# N32H488 register map
Vendor: Nationstech Ltd.; File version: 1.0
Registers are 32-bit, read-write, reset 0x0 unless marked. A register's access mark holds for its fields unless they carry their own. Offsets are from the block's base; [hi:lo] are bit positions; {n}, {i} and the like mark numbered series.

## FMAC — Filter math accelerator
Base 0x40021C00
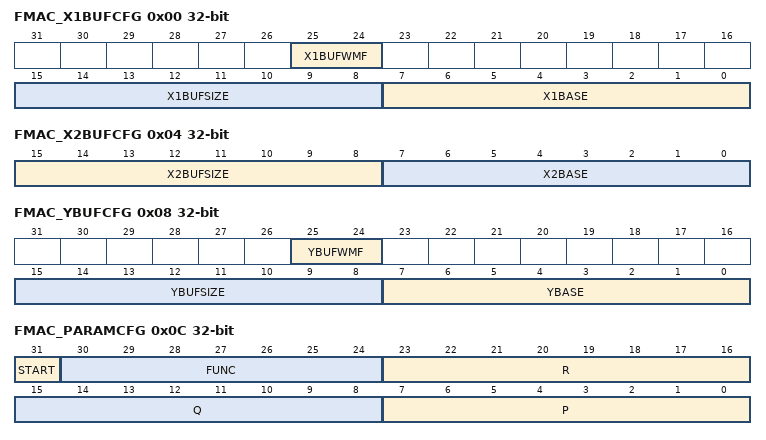
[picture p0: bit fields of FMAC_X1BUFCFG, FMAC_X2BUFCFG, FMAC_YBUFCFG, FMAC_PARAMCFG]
0x00 FMAC_X1BUFCFG
  [25:24] X1BUFWMF, [15:8] X1BUFSIZE, [7:0] X1BASE
0x04 FMAC_X2BUFCFG
  [15:8] X2BUFSIZE, [7:0] X2BASE
0x08 FMAC_YBUFCFG
  [25:24] YBUFWMF, [15:8] YBUFSIZE, [7:0] YBASE
0x0C FMAC_PARAMCFG
  [31] START, [30:24] FUNC, [23:16] R, [15:8] Q, [7:0] P
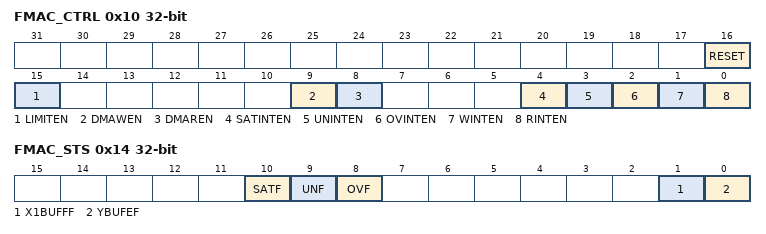
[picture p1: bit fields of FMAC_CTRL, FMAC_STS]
0x10 FMAC_CTRL
  [16] RESET, [15] LIMITEN, [9] DMAWEN, [8] DMAREN, [4] SATINTEN, [3] UNINTEN, [2] OVINTEN, [1] WINTEN, [0] RINTEN
0x14 FMAC_STS
  [10] SATF, [9] UNF, [8] OVF, [1] X1BUFFF, [0] YBUFEF
0x18 FMAC_WDAT
  [15:0] WDAT
0x1C FMAC_RDAT
  [15:0] RDAT

## CORDIC
Base 0x40022400
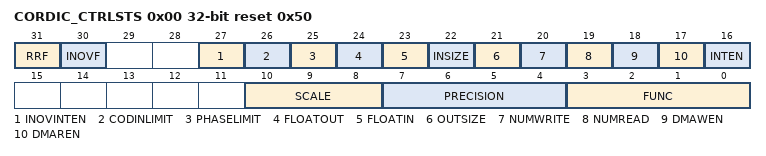
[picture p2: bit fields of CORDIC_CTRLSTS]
0x00 CORDIC_CTRLSTS reset 0x50
  [31] RRF, [30] INOVF, [27] INOVINTEN, [26] CODINLIMIT, [25] PHASELIMIT, [24] FLOATOUT, [23] FLOATIN, [22] INSIZE, [21] OUTSIZE, [20] NUMWRITE, [19] NUMREAD, [18] DMAWEN, [17] DMAREN, [16] INTEN, [10:8] SCALE, [7:4] PRECISION, [3:0] FUNC
0x04 CORDIC_WDAT
0x08 CORDIC_RDAT

## CRC — cyclic redundancy check
Base 0x40021800
0x00 CRC_CRC32CTRL
  [0] RESET
0x04 CRC_CRC32DAT reset 0xFFFFFFFF
0x08 CRC_CRC32IDAT
  [7:0] CRC32IDAT
0x0C CRC_CRC32D reset 0xFFFFFFFF
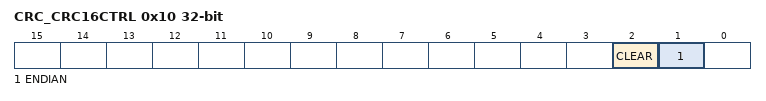
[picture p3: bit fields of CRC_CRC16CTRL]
0x10 CRC_CRC16CTRL
  [2] CLEAR, [1] ENDIAN
0x14 CRC_CRC16DAT
  [7:0] CRC16DAT
0x18 CRC_CRC16D
  [15:0] CRC16D
0x1C CRC_LRC
  [7:0] LRCDAT

## xSPI — Multi-line SPI
Base 0xA0001000
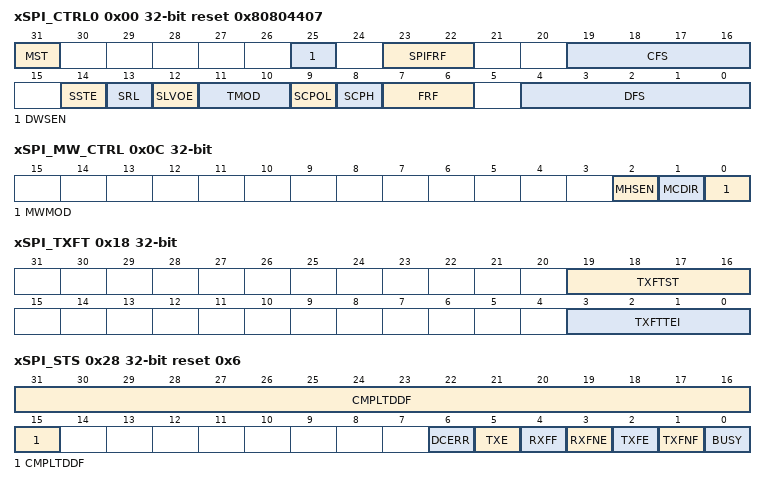
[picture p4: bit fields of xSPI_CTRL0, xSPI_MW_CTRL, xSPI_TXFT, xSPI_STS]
0x00 xSPI_CTRL0 reset 0x80804407
  [31] MST, [25] DWSEN, [23:22] SPIFRF, [19:16] CFS, [14] SSTE, [13] SRL, [12] SLVOE, [11:10] TMOD, [9] SCPOL, [8] SCPH, [7:6] FRF, [4:0] DFS
0x04 xSPI_CTRL1
  [15:0] NDF
0x08 xSPI_EN
  [0] xSPIEN
0x0C xSPI_MW_CTRL
  [2] MHSEN, [1] MCDIR, [0] MWMOD
0x10 xSPI_SLAVE_EN
  [1:0] SEN
0x14 xSPI_BAUD
  [15:1] CLKDIV
0x18 xSPI_TXFT
  [19:16] TXFTST, [3:0] TXFTTEI
0x1C xSPI_RXFT
  [3:0] RXFTTFI
0x20 xSPI_TXFN
  [4:0] TXFN
0x24 xSPI_RXFN
  [4:0] RXFN
0x28 xSPI_STS reset 0x6
  [31:15] CMPLTDDF, [6] DCERR, [5] TXE, [4] RXFF, [3] RXFNE, [2] TXFE, [1] TXFNF, [0] BUSY
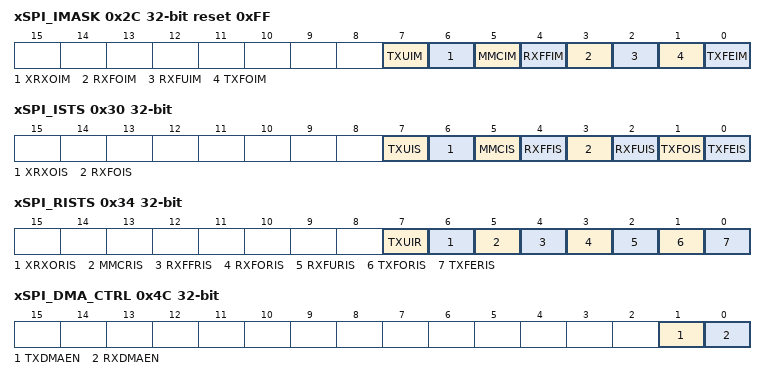
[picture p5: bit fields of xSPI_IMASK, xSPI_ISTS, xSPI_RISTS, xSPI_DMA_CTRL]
0x2C xSPI_IMASK reset 0xFF
  [7] TXUIM, [6] XRXOIM, [5] MMCIM, [4] RXFFIM, [3] RXFOIM, [2] RXFUIM, [1] TXFOIM, [0] TXFEIM
0x30 xSPI_ISTS
  [7] TXUIS, [6] XRXOIS, [5] MMCIS, [4] RXFFIS, [3] RXFOIS, [2] RXFUIS, [1] TXFOIS, [0] TXFEIS
0x34 xSPI_RISTS
  [7] TXUIR, [6] XRXORIS, [5] MMCRIS, [4] RXFFRIS, [3] RXFORIS, [2] RXFURIS, [1] TXFORIS, [0] TXFERIS
0x38 xSPI_TXEICR_CLR
  [0] TXEICR
0x3C xSPI_RXFOI_CLR
  [0] RXFOIC
0x40 xSPI_RXFUI_CLR
  [0] RXFUIC
0x44 xSPI_MMC_CLR
  [0] MMCIC
0x48 xSPI_ICLR
  [0] INTC
0x4C xSPI_DMA_CTRL
  [1] TXDMAEN, [0] RXDMAEN
0x50 xSPI_DMATDL_CTRL
  [3:0] DMATDL
0x54 xSPI_DMARDL_CTRL
  [3:0] DMARDL
0x58 xSPI_IDR reset 0xFFFF3621
  [31:0] IDCODE
0x5C xSPI_VERSION_ID reset 0x3130332A
  [31:0] VERSION
0x60 xSPI_DATx
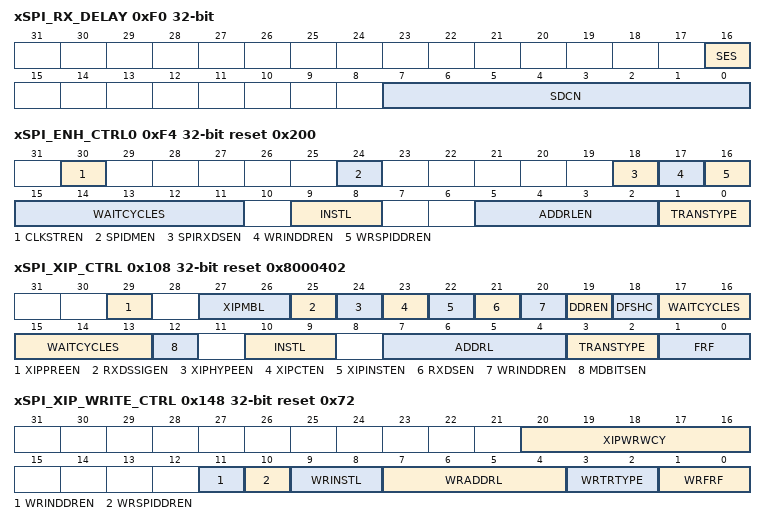
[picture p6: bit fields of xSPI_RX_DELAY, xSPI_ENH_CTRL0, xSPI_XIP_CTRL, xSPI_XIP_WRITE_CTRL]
0xF0 xSPI_RX_DELAY
  [16] SES, [7:0] SDCN
0xF4 xSPI_ENH_CTRL0 reset 0x200
  [30] CLKSTREN, [24] SPIDMEN, [18] SPIRXDSEN, [17] WRINDDREN, [16] WRSPIDDREN, [15:11] WAITCYCLES, [9:8] INSTL, [5:2] ADDRLEN, [1:0] TRANSTYPE
0xF8 xSPI_DDR_TXDE
  [7:0] TXDE
0xFC xSPI_XIP_MODE
  [15:0] XIPMDBITS
0x100 xSPI_XIP_INCR_TOC
  [15:0] ITOC
0x104 xSPI_XIP_WRAP_TOC
  [15:0] WTOC
0x108 xSPI_XIP_CTRL reset 0x8000402
  [29] XIPPREEN, [27:26] XIPMBL, [25] RXDSSIGEN, [24] XIPHYPEEN, [23] XIPCTEN, [22] XIPINSTEN, [21] RXDSEN, [20] WRINDDREN, [19] DDREN, [18] DFSHC, [17:13] WAITCYCLES, [12] MDBITSEN, [10:9] INSTL, [7:4] ADDRL, [3:2] TRANSTYPE, [1:0] FRF
0x10C xSPI_XIP_SLAVE_EN
  [1:0] SEN
0x110 xSPI_XIP_RXFOI_CLR
  [0] XRXFOIC
0x114 xSPI_XIP_TOUT
  [7:0] XTOUT
0x140 xSPI_XIP_WRITE_INCR_INST
  [15:0] INCRWRINST
0x144 xSPI_XIP_WRITE_WRAP_INST
  [15:0] WRAPWRINST
0x148 xSPI_XIP_WRITE_CTRL reset 0x72
  [20:16] XIPWRWCY, [11] WRINDDREN, [10] WRSPIDDREN, [9:8] WRINSTL, [7:4] WRADDRL, [3:2] WRTRTYPE, [1:0] WRFRF

## ATIM1 — Advanced timer
Base 0x40032000
Same registers: ATIM2 0x40032400, ATIM3 0x40032800
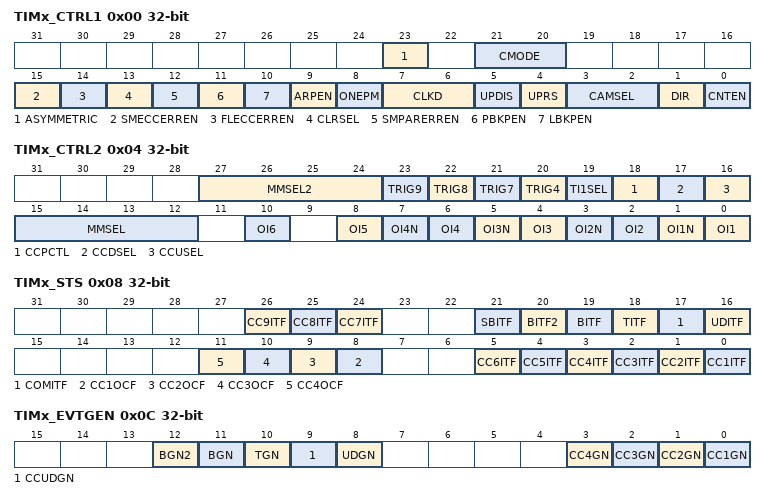
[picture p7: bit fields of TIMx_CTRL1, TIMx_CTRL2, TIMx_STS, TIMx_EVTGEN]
0x00 TIMx_CTRL1
  [23] ASYMMETRIC, [21:20] CMODE, [15] SMECCERREN, [14] FLECCERREN, [13] CLRSEL, [12] SMPARERREN, [11] PBKPEN, [10] LBKPEN, [9] ARPEN, [8] ONEPM, [7:6] CLKD, [5] UPDIS, [4] UPRS, [3:2] CAMSEL, [1] DIR, [0] CNTEN
0x04 TIMx_CTRL2
  [27:24] MMSEL2, [23] TRIG9, [22] TRIG8, [21] TRIG7, [20] TRIG4, [19] TI1SEL, [18] CCPCTL, [17] CCDSEL, [16] CCUSEL, [15:12] MMSEL, [2n-2] OI{n} (n=1..6), [2n-1] OI{n}N (n=1..4)
0x08 TIMx_STS
  [26] CC9ITF, [25] CC8ITF, [24] CC7ITF, [21] SBITF, [20] BITF2, [19] BITF, [18] TITF, [17] COMITF, [16] UDITF, [n+7] CC{n}OCF (n=1..4), [n-1] CC{n}ITF (n=1..6)
0x0C TIMx_EVTGEN
  [12] BGN2, [11] BGN, [10] TGN, [9] CCUDGN, [8] UDGN, [n-1] CC{n}GN (n=1..4)
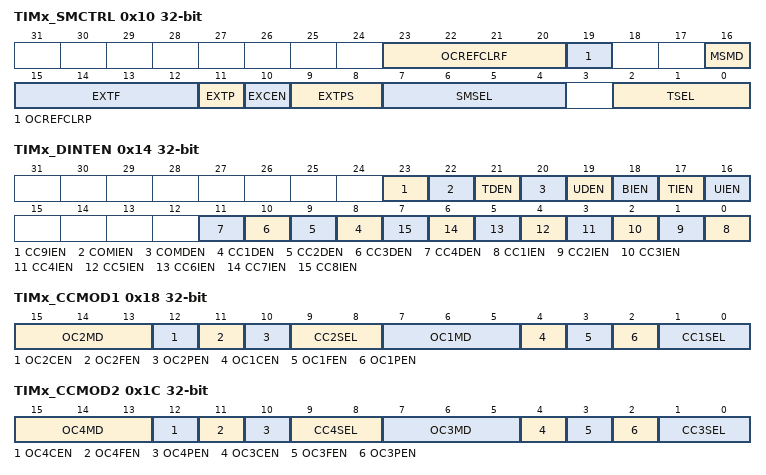
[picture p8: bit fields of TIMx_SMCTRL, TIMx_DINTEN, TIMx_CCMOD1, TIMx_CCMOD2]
0x10 TIMx_SMCTRL
  [23:20] OCREFCLRF, [19] OCREFCLRP, [16] MSMD, [15:12] EXTF, [11] EXTP, [10] EXCEN, [9:8] EXTPS, [7:4] SMSEL, [2:0] TSEL
0x14 TIMx_DINTEN
  [23] CC9IEN, [22] COMIEN, [21] TDEN, [20] COMDEN, [19] UDEN, [18] BIEN, [17] TIEN, [16] UIEN, [n+7] CC{n}DEN (n=1..4), [n-1] CC{n}IEN (n=1..8)
0x18 TIMx_CCMOD1
  [15:13] OC2MD, [12] OC2CEN, [11] OC2FEN, [10] OC2PEN, [9:8] CC2SEL, [7:5] OC1MD, [4] OC1CEN, [3] OC1FEN, [2] OC1PEN, [1:0] CC1SEL
0x1C TIMx_CCMOD2
  [15:13] OC4MD, [12] OC4CEN, [11] OC4FEN, [10] OC4PEN, [9:8] CC4SEL, [7:5] OC3MD, [4] OC3CEN, [3] OC3FEN, [2] OC3PEN, [1:0] CC3SEL
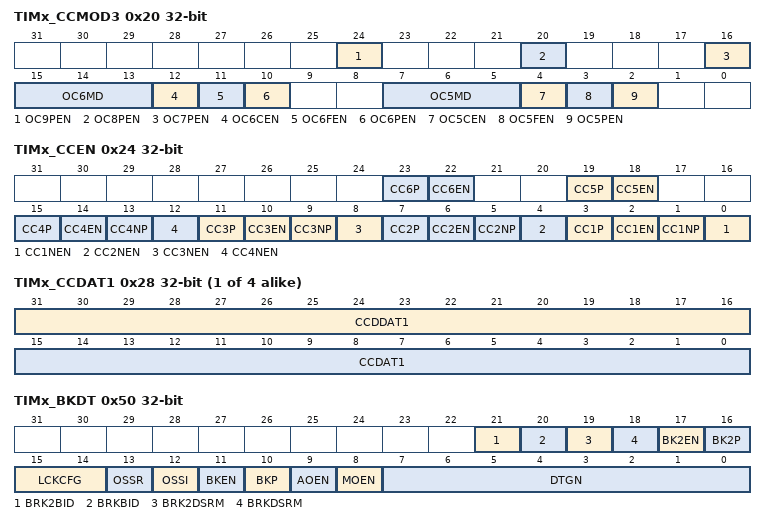
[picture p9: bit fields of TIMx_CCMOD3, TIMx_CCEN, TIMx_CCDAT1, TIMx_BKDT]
0x20 TIMx_CCMOD3
  [24] OC9PEN, [20] OC8PEN, [16] OC7PEN, [15:13] OC6MD, [12] OC6CEN, [11] OC6FEN, [10] OC6PEN, [7:5] OC5MD, [4] OC5CEN, [3] OC5FEN, [2] OC5PEN
0x24 TIMx_CCEN
  [4n-1] CC{n}P (n=1..6), [4n-2] CC{n}EN (n=1..6), [4n-3] CC{n}NP (n=1..4), [4n-4] CC{n}NEN (n=1..4)
{0x24+4i} TIMx_CCDAT{i} (i=1..4)
  [31:16] CCDDAT{i}, [15:0] CCDAT{i}
0x38 TIMx_CCDAT5
  [15:0] CCDAT5
0x3C TIMx_CCDAT6
  [15:0] CCDAT6
0x40 TIMx_PSC
  [15:0] PSC
0x44 TIMx_AR reset 0xFFFF
  [15:0] AR
0x48 TIMx_CNT
  [15:0] CNT
0x4C TIMx_REPCNT
  [7:0] REPCNT
0x50 TIMx_BKDT
  [21] BRK2BID, [20] BRKBID, [19] BRK2DSRM, [18] BRKDSRM, [17] BK2EN, [16] BK2P, [15:14] LCKCFG, [13] OSSR, [12] OSSI, [11] BKEN, [10] BKP, [9] AOEN, [8] MOEN, [7:0] DTGN
{0x38+4i} TIMx_CCDAT{i} (i=7..9)
  [15:0] CCDAT{i}
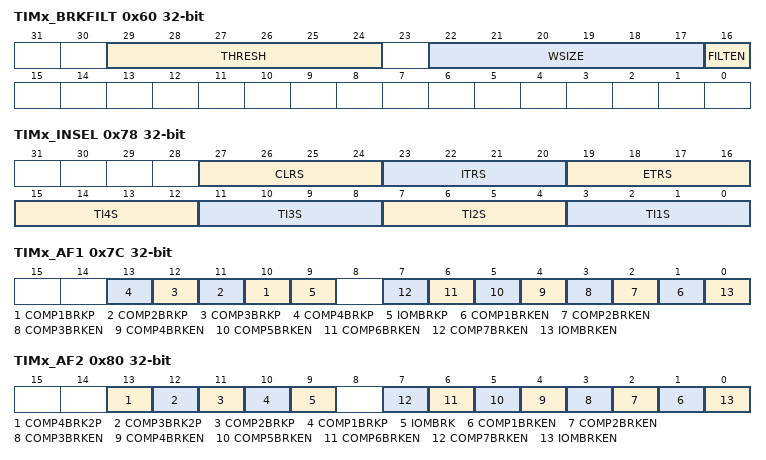
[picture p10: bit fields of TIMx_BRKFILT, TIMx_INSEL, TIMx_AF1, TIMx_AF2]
0x60 TIMx_BRKFILT
  [29:24] THRESH, [22:17] WSIZE, [16] FILTEN
0x78 TIMx_INSEL
  [27:24] CLRS, [23:20] ITRS, [19:16] ETRS, [4n-1:4n-4] TI{n}S (n=1..4)
0x7C TIMx_AF1
  [n+9] COMP{n}BRKP (n=1..4), [9] IOMBRKP, [n] COMP{n}BRKEN (n=1..7), [0] IOMBRKEN
0x80 TIMx_AF2
  [13] COMP4BRK2P, [12] COMP3BRK2P, [11] COMP2BRKP, [10] COMP1BRKP, [9] IOMBRK, [n] COMP{n}BRKEN (n=1..7), [0] IOMBRKEN
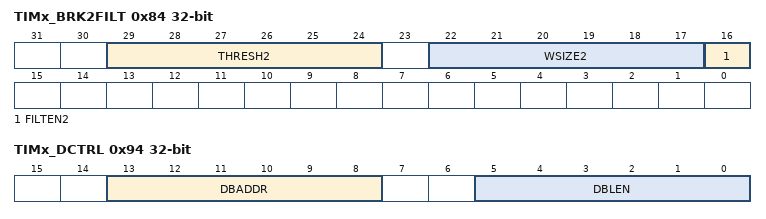
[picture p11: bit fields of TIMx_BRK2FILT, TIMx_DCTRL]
0x84 TIMx_BRK2FILT
  [29:24] THRESH2, [22:17] WSIZE2, [16] FILTEN2
0x88 TIMx_SLIDFPSC
  [15:0] SLIDFPSC
0x94 TIMx_DCTRL
  [13:8] DBADDR, [5:0] DBLEN
0x98 TIMx_DADDR
  [31:0] BURST
